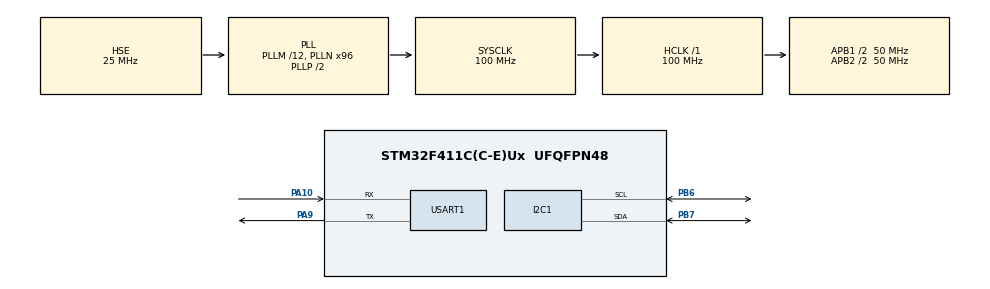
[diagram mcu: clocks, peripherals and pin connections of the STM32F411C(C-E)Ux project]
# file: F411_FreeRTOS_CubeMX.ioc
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Dma.Request0=USART1_RX
Dma.Request1=USART1_TX
Dma.USART1_RX.0.Direction=DMA_PERIPH_TO_MEMORY
Dma.USART1_RX.0.FIFOMode=DMA_FIFOMODE_DISABLE
Dma.USART1_RX.0.Instance=DMA2_Stream2
Dma.USART1_RX.0.MemDataAlignment=DMA_MDATAALIGN_BYTE
Dma.USART1_RX.0.MemInc=DMA_MINC_ENABLE
Dma.USART1_RX.0.Mode=DMA_CIRCULAR
Dma.USART1_RX.0.PeriphDataAlignment=DMA_PDATAALIGN_BYTE
Dma.USART1_RX.0.PeriphInc=DMA_PINC_DISABLE
Dma.USART1_RX.0.Priority=DMA_PRIORITY_LOW
Dma.USART1_TX.1.Direction=DMA_MEMORY_TO_PERIPH
Dma.USART1_TX.1.FIFOMode=DMA_FIFOMODE_DISABLE
Dma.USART1_TX.1.Instance=DMA2_Stream7
Dma.USART1_TX.1.MemDataAlignment=DMA_MDATAALIGN_BYTE
Dma.USART1_TX.1.MemInc=DMA_MINC_ENABLE
Dma.USART1_TX.1.Mode=DMA_NORMAL
Dma.USART1_TX.1.PeriphDataAlignment=DMA_PDATAALIGN_BYTE
Dma.USART1_TX.1.PeriphInc=DMA_PINC_DISABLE
Dma.USART1_TX.1.Priority=DMA_PRIORITY_LOW
FREERTOS.Tasks01=defaultTask,24,128,StartDefaultTask,Default,NULL,Dynamic,NULL,NULL
I2C1.I2C_Mode=I2C_Standard
Mcu.Family=STM32F4
Mcu.Name=STM32F411C(C-E)Ux
Mcu.Package=UFQFPN48
NVIC.DMA2_Stream2_IRQn=true\:5\:0\:false\:false\:true\:true\:false\:true\:true
NVIC.DMA2_Stream7_IRQn=true\:5\:0\:false\:false\:true\:true\:false\:true\:true
NVIC.PriorityGroup=NVIC_PRIORITYGROUP_4
NVIC.TIM1_UP_TIM10_IRQn=true\:15\:0\:false\:false\:true\:false\:false\:true\:true
NVIC.TimeBase=TIM1_UP_TIM10_IRQn
NVIC.TimeBaseIP=TIM1
NVIC.USART1_IRQn=true\:5\:0\:false\:false\:true\:true\:true\:true\:true
PA10.Mode=Asynchronous
PA10.Signal=USART1_RX
PA13.Mode=Serial_Wire
PA13.Signal=SYS_JTMS-SWDIO
PA14.Mode=Serial_Wire
PA14.Signal=SYS_JTCK-SWCLK
PA9.Mode=Asynchronous
PA9.Signal=USART1_TX
PB6.Mode=I2C
PB6.Signal=I2C1_SCL
PB7.Mode=I2C
PB7.Signal=I2C1_SDA
PH0\ -\ OSC_IN.Mode=HSE-External-Oscillator
PH0\ -\ OSC_IN.Signal=RCC_OSC_IN
PH1\ -\ OSC_OUT.Mode=HSE-External-Oscillator
PH1\ -\ OSC_OUT.Signal=RCC_OSC_OUT
ProjectManager.HeapSize=0x800
ProjectManager.StackSize=0x800
ProjectManager.TargetToolchain=MDK-ARM V5.32
RCC.48MHZClocksFreq_Value=50000000
RCC.AHBFreq_Value=100000000
RCC.APB1CLKDivider=RCC_HCLK_DIV2
RCC.APB1Freq_Value=50000000
RCC.APB1TimFreq_Value=100000000
RCC.APB2CLKDivider=RCC_HCLK_DIV2
RCC.APB2Freq_Value=50000000
RCC.APB2TimFreq_Value=100000000
RCC.CortexFreq_Value=100000000
RCC.HCLKFreq_Value=100000000
RCC.HSE_VALUE=25000000
RCC.HSI_VALUE=16000000
RCC.LSE_VALUE=32768
RCC.PLLM=12
RCC.PLLN=96
RCC.PLLSourceVirtual=RCC_PLLSOURCE_HSE
RCC.SYSCLKFreq_VALUE=100000000
RCC.SYSCLKSource=RCC_SYSCLKSOURCE_PLLCLK
RCC.VCOOutputFreq_Value=200000000
STMicroelectronics.X-CUBE-AI.10.2.0.ActivationBufferSizeList=6184
STMicroelectronics.X-CUBE-AI.10.2.0.ActivationBuffers=pool0
STMicroelectronics.X-CUBE-AI.10.2.0.ActivationNames=pool0
STMicroelectronics.X-CUBE-AI.10.2.0.ActivationSizes=AI_NETWORK_DATA_ACTIVATION_1_SIZE
STMicroelectronics.X-CUBE-AI.10.2.0.HeapSize=0x800
STMicroelectronics.X-CUBE-AI.10.2.0.InternalRamActivationBufferMaxSize=AI_NETWORK_DATA_ACTIVATIONS_SIZE
STMicroelectronics.X-CUBE-AI.10.2.0.LatestDirectoryUsed-924c96b226166df5709fa971748c2927a9a61541431449f4dc40a3f7f46526ca=G\:\\Cursor\\kato-modbus\\Simulation\\algorithm\\Data\\06_1DCNN
STMicroelectronics.X-CUBE-AI.10.2.0.MaximumNumberOfInputLayer=1
STMicroelectronics.X-CUBE-AI.10.2.0.MaximumNumberOfOutputLayer=1
STMicroelectronics.X-CUBE-AI.10.2.0.MaximumSizeOfInputLayer=1
STMicroelectronics.X-CUBE-AI.10.2.0.MaximumSizeOfOutputLayer=1
STMicroelectronics.X-CUBE-AI.10.2.0.ModelActualCompression-924c96b226166df5709fa971748c2927a9a61541431449f4dc40a3f7f46526ca=0.0
STMicroelectronics.X-CUBE-AI.10.2.0.ModelCompression-924c96b226166df5709fa971748c2927a9a61541431449f4dc40a3f7f46526ca=None
STMicroelectronics.X-CUBE-AI.10.2.0.ModelFlashOccupation-924c96b226166df5709fa971748c2927a9a61541431449f4dc40a3f7f46526ca=23272
STMicroelectronics.X-CUBE-AI.10.2.0.ModelHashList=924c96b226166df5709fa971748c2927a9a61541431449f4dc40a3f7f46526ca
STMicroelectronics.X-CUBE-AI.10.2.0.ModelKind-924c96b226166df5709fa971748c2927a9a61541431449f4dc40a3f7f46526ca=ONNX
STMicroelectronics.X-CUBE-AI.10.2.0.ModelMacc-924c96b226166df5709fa971748c2927a9a61541431449f4dc40a3f7f46526ca=78882
STMicroelectronics.X-CUBE-AI.10.2.0.ModelName-924c96b226166df5709fa971748c2927a9a61541431449f4dc40a3f7f46526ca=network
STMicroelectronics.X-CUBE-AI.10.2.0.ModelNameList=network
STMicroelectronics.X-CUBE-AI.10.2.0.ModelRamOccupation-924c96b226166df5709fa971748c2927a9a61541431449f4dc40a3f7f46526ca=6184
STMicroelectronics.X-CUBE-AI.10.2.0.ModelStructureFile-924c96b226166df5709fa971748c2927a9a61541431449f4dc40a3f7f46526ca=G\:\\Cursor\\kato-modbus\\Simulation\\algorithm\\Data\\06_1DCNN\\f411_model.onnx
STMicroelectronics.X-CUBE-AI.10.2.0.ModelType-924c96b226166df5709fa971748c2927a9a61541431449f4dc40a3f7f46526ca=STM32Cube.AI MCU runtime
STMicroelectronics.X-CUBE-AI.10.2.0.ReadyForCodeGeneration=true
STMicroelectronics.X-CUBE-AI.10.2.0.StackSize=0x800
STMicroelectronics.X-CUBE-AI.10.2.0.WorkingBufferStartAddrList=0xFFFFFFFF
STMicroelectronics.X-CUBE-AI.10.2.0.XAaCUBEAaAICcArtificialOoIntelligenceJjCore=true
STMicroelectronics.X-CUBE-AI.10.2.0.copyWeightToRam=false
STMicroelectronics.X-CUBE-AI.10.2.0.copyWeightToRam-924c96b226166df5709fa971748c2927a9a61541431449f4dc40a3f7f46526ca=false
STMicroelectronics.X-CUBE-AI.10.2.0.customLayerConfigEnabled=false
STMicroelectronics.X-CUBE-AI.10.2.0.customLayerConfigEnabled-924c96b226166df5709fa971748c2927a9a61541431449f4dc40a3f7f46526ca=false
STMicroelectronics.X-CUBE-AI.10.2.0.noOnnxIoTranspose=false
STMicroelectronics.X-CUBE-AI.10.2.0.noOnnxIoTranspose-924c96b226166df5709fa971748c2927a9a61541431449f4dc40a3f7f46526ca=false
STMicroelectronics.X-CUBE-AI.10.2.0.useInputAllocation=true
STMicroelectronics.X-CUBE-AI.10.2.0.useInputAllocation-924c96b226166df5709fa971748c2927a9a61541431449f4dc40a3f7f46526ca=true
STMicroelectronics.X-CUBE-AI.10.2.0.useOutputAllocation=true
STMicroelectronics.X-CUBE-AI.10.2.0.useOutputAllocation-924c96b226166df5709fa971748c2927a9a61541431449f4dc40a3f7f46526ca=true
USART1.VirtualMode=VM_ASYNC
VP_FREERTOS_VS_CMSIS_V2.Mode=CMSIS_V2
VP_STMicroelectronics.X-CUBE-AI_VS_ArtificialOoIntelligenceJjXAaCUBEAaAI_10.2.0.Mode=ArtificialOoIntelligenceJjXAaCUBEAaAI
VP_SYS_VS_tim1.Mode=TIM1
board=custom

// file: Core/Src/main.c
/* USER CODE BEGIN Header */
/**
  ******************************************************************************
  * @file           : main.c
  * @brief          : Main program body
  ******************************************************************************
  * @attention
  *
  * Copyright (c) 2026 STMicroelectronics.
  * All rights reserved.
  *
  * This software is licensed under terms that can be found in the LICENSE file
  * in the root directory of this software component.
  * If no LICENSE file comes with this software, it is provided AS-IS.
  *
  ******************************************************************************
  */
/* USER CODE END Header */
#include "main.h"
#include "cmsis_os.h"
#include "dma.h"
#include "i2c.h"
#include "usart.h"
#include "gpio.h"

void SystemClock_Config(void);
void MX_FREERTOS_Init(void);

int main(void)
{

  /* MCU Configuration--------------------------------------------------------*/

  /* Reset of all peripherals, Initializes the Flash interface and the Systick. */
  HAL_Init();

  /* Configure the system clock */
  SystemClock_Config();

  /* Initialize all configured peripherals */
  MX_GPIO_Init();
  MX_DMA_Init();
  MX_USART1_UART_Init();
  MX_I2C1_Init();

  /* Init scheduler */
  osKernelInitialize();

  /* Call init function for freertos objects (in cmsis_os2.c) */
  MX_FREERTOS_Init();

  /* Start scheduler */
  osKernelStart();

  /* We should never get here as control is now taken by the scheduler */

  /* Infinite loop */
  while (1)
  {

  }
}

void SystemClock_Config(void)
{
  RCC_OscInitTypeDef RCC_OscInitStruct = {0};
  RCC_ClkInitTypeDef RCC_ClkInitStruct = {0};

  /** Configure the main internal regulator output voltage
  */
  __HAL_RCC_PWR_CLK_ENABLE();
  __HAL_PWR_VOLTAGESCALING_CONFIG(PWR_REGULATOR_VOLTAGE_SCALE1);

  /** Initializes the RCC Oscillators according to the specified parameters
  * in the RCC_OscInitTypeDef structure.
  */
  RCC_OscInitStruct.OscillatorType = RCC_OSCILLATORTYPE_HSE;
  RCC_OscInitStruct.HSEState = RCC_HSE_ON;
  RCC_OscInitStruct.PLL.PLLState = RCC_PLL_ON;
  RCC_OscInitStruct.PLL.PLLSource = RCC_PLLSOURCE_HSE;
  RCC_OscInitStruct.PLL.PLLM = 12;
  RCC_OscInitStruct.PLL.PLLN = 96;
  RCC_OscInitStruct.PLL.PLLP = RCC_PLLP_DIV2;
  RCC_OscInitStruct.PLL.PLLQ = 4;
  if (HAL_RCC_OscConfig(&RCC_OscInitStruct) != HAL_OK)
  {
    Error_Handler();
  }

  /** Initializes the CPU, AHB and APB buses clocks
  */
  RCC_ClkInitStruct.ClockType = RCC_CLOCKTYPE_HCLK|RCC_CLOCKTYPE_SYSCLK
                              |RCC_CLOCKTYPE_PCLK1|RCC_CLOCKTYPE_PCLK2;
  RCC_ClkInitStruct.SYSCLKSource = RCC_SYSCLKSOURCE_PLLCLK;
  RCC_ClkInitStruct.AHBCLKDivider = RCC_SYSCLK_DIV1;
  RCC_ClkInitStruct.APB1CLKDivider = RCC_HCLK_DIV2;
  RCC_ClkInitStruct.APB2CLKDivider = RCC_HCLK_DIV2;

  if (HAL_RCC_ClockConfig(&RCC_ClkInitStruct, FLASH_LATENCY_3) != HAL_OK)
  {
    Error_Handler();
  }
}

void HAL_TIM_PeriodElapsedCallback(TIM_HandleTypeDef *htim)
{
  if (htim->Instance == TIM1)
  {
    HAL_IncTick();
  }
}

void Error_Handler(void)
{
  __disable_irq();
  while (1)
  {
  }
}

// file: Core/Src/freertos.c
/* USER CODE BEGIN Header */
/**
  ******************************************************************************
  * File Name          : freertos.c
  * Description        : Code for freertos applications
  ******************************************************************************
  * @attention
  *
  * Copyright (c) 2026 STMicroelectronics.
  * All rights reserved.
  *
  * This software is licensed under terms that can be found in the LICENSE file
  * in the root directory of this software component.
  * If no LICENSE file comes with this software, it is provided AS-IS.
  *
  ******************************************************************************
  */
/* USER CODE END Header */

#include "FreeRTOS.h"
#include "task.h"
#include "main.h"
#include "cmsis_os.h"

/* USER CODE BEGIN Includes */
#include "bsp_usart.h"
#include "inference_task.h"
#include "sensor_task.h"
/* USER CODE END Includes */

/* Definitions for defaultTask */
osThreadId_t defaultTaskHandle;
const osThreadAttr_t defaultTask_attributes = {
  .name = "defaultTask",
  .stack_size = 128 * 4,
  .priority = (osPriority_t) osPriorityNormal,
};

void StartDefaultTask(void *argument);

void MX_FREERTOS_Init(void); /* (MISRA C 2004 rule 8.1) */

void MX_FREERTOS_Init(void) {

  /* Create the thread(s) */
  /* creation of defaultTask */
  defaultTaskHandle = osThreadNew(StartDefaultTask, NULL, &defaultTask_attributes);

  /* USER CODE BEGIN RTOS_THREADS */
  InferenceTask_Init();
  SensorTask_Init();
  /* USER CODE END RTOS_THREADS */

}

void StartDefaultTask(void *argument)
{
  /* USER CODE BEGIN StartDefaultTask */

  /* 初始化串口 BSP（在调度器启动后、任务里调用） */
  BSP_USART1_Init();

  BSP_USART1_Print("USART1 ready\r\n");

  USART1_Frame_t frame;

  for(;;)
  {
    /* 阻塞等待接收数据，收到后立即回显 */
    if (BSP_USART1_Receive(&frame, portMAX_DELAY) == pdPASS)
    {
      /* 回显收到的数据 */
      BSP_USART1_Send(frame.data, frame.len);

      /* 打印调试信息 */
      BSP_USART1_Printf("RX: %d bytes\r\n", frame.len);
    }
  }
  /* USER CODE END StartDefaultTask */
}
